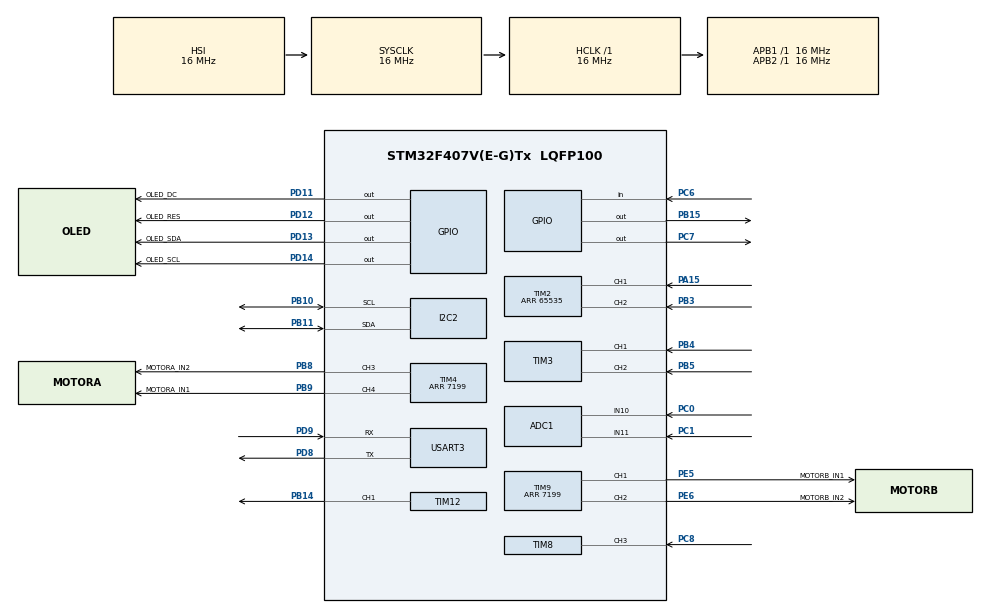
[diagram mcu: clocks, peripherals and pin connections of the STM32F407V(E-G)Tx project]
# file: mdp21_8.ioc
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ADC1.Channel-0\#ChannelRegularConversion=ADC_CHANNEL_10
ADC1.Channel-1\#ChannelRegularConversion=ADC_CHANNEL_11
ADC1.ClockPrescaler=ADC_CLOCK_SYNC_PCLK_DIV4
ADC1.NbrOfConversion=2
ADC1.NbrOfConversionFlag=1
ADC1.Rank-0\#ChannelRegularConversion=1
ADC1.Rank-1\#ChannelRegularConversion=2
ADC1.SamplingTime-0\#ChannelRegularConversion=ADC_SAMPLETIME_144CYCLES
ADC1.SamplingTime-1\#ChannelRegularConversion=ADC_SAMPLETIME_144CYCLES
ADC1.ScanConvMode=ENABLE
ADC1.master=1
FREERTOS.Tasks01=defaultTask,24,128,StartDefaultTask,Default,NULL,Dynamic,NULL,NULL
Mcu.Family=STM32F4
Mcu.Name=STM32F407V(E-G)Tx
Mcu.Package=LQFP100
NVIC.PriorityGroup=NVIC_PRIORITYGROUP_4
NVIC.TIM6_DAC_IRQn=true\:15\:0\:false\:false\:true\:false\:false\:true\:true
NVIC.TIM8_CC_IRQn=true\:5\:0\:false\:false\:true\:true\:true\:true\:true
NVIC.TimeBase=TIM6_DAC_IRQn
NVIC.TimeBaseIP=TIM6
NVIC.USART3_IRQn=true\:5\:0\:true\:false\:true\:true\:true\:true\:true
PA13.Mode=Serial_Wire
PA13.Signal=SYS_JTMS-SWDIO
PA14.Mode=Serial_Wire
PA14.Signal=SYS_JTCK-SWCLK
PA15.Signal=S_TIM2_CH1_ETR
PB10.Mode=I2C
PB10.Signal=I2C2_SCL
PB11.Mode=I2C
PB11.Signal=I2C2_SDA
PB14.Signal=S_TIM12_CH1
PB15.Signal=GPIO_Output
PB3.Signal=S_TIM2_CH2
PB4.Signal=S_TIM3_CH1
PB5.Signal=S_TIM3_CH2
PB8.GPIO_Label=MOTORA_IN2
PB8.Signal=S_TIM4_CH3
PB9.GPIO_Label=MOTORA_IN1
PB9.Signal=S_TIM4_CH4
PC0.Signal=ADCx_IN10
PC1.Signal=ADCx_IN11
PC6.Signal=GPIO_Input
PC7.Signal=GPIO_Output
PC8.Signal=S_TIM8_CH3
PD11.GPIO_Label=OLED_DC
PD11.GPIO_Speed=GPIO_SPEED_FREQ_HIGH
PD11.Signal=GPIO_Output
PD12.GPIO_Label=OLED_RES
PD12.PinState=GPIO_PIN_SET
PD12.Signal=GPIO_Output
PD13.GPIO_Label=OLED_SDA
PD13.GPIO_Speed=GPIO_SPEED_FREQ_HIGH
PD13.Signal=GPIO_Output
PD14.GPIO_Label=OLED_SCL
PD14.GPIO_Speed=GPIO_SPEED_FREQ_HIGH
PD14.Signal=GPIO_Output
PD8.Mode=Asynchronous
PD8.Signal=USART3_TX
PD9.Mode=Asynchronous
PD9.Signal=USART3_RX
PE5.GPIO_Label=MOTORB_IN1
PE5.Signal=S_TIM9_CH1
PE6.GPIO_Label=MOTORB_IN2
PE6.Signal=S_TIM9_CH2
ProjectManager.HeapSize=0x200
ProjectManager.StackSize=0x400
ProjectManager.TargetToolchain=STM32CubeIDE
RCC.AHBFreq_Value=16000000
RCC.APB1Freq_Value=16000000
RCC.APB2Freq_Value=16000000
RCC.CortexFreq_Value=16000000
RCC.HSE_VALUE=25000000
RCC.HSI_VALUE=16000000
RCC.LSE_VALUE=32768
RCC.SYSCLKFreq_VALUE=16000000
RCC.VCOOutputFreq_Value=192000000
SH.ADCx_IN10.0=ADC1_IN10,IN10
SH.ADCx_IN11.0=ADC1_IN11,IN11
SH.S_TIM12_CH1.0=TIM12_CH1,PWM Generation1 CH1
SH.S_TIM2_CH1_ETR.0=TIM2_CH1,Encoder_Interface
SH.S_TIM2_CH2.0=TIM2_CH2,Encoder_Interface
SH.S_TIM3_CH1.0=TIM3_CH1,Encoder_Interface
SH.S_TIM3_CH2.0=TIM3_CH2,Encoder_Interface
SH.S_TIM4_CH3.0=TIM4_CH3,PWM Generation3 CH3
SH.S_TIM4_CH4.0=TIM4_CH4,PWM Generation4 CH4
SH.S_TIM8_CH3.0=TIM8_CH3,Input_Capture3_from_TI3
SH.S_TIM9_CH1.0=TIM9_CH1,PWM Generation1 CH1
SH.S_TIM9_CH2.0=TIM9_CH2,PWM Generation2 CH2
TIM12.Channel-PWM\ Generation1\ CH1=TIM_CHANNEL_1
TIM12.Period=19999
TIM12.Prescaler=15
TIM12.Pulse-PWM\ Generation1\ CH1=1500
TIM2.EncoderMode=TIM_ENCODERMODE_TI12
TIM2.IC1Filter=10
TIM2.IC2Filter=10
TIM2.Period=65535
TIM3.EncoderMode=TIM_ENCODERMODE_TI12
TIM3.IC1Filter=10
TIM3.IC2Filter=10
TIM4.Channel-PWM\ Generation3\ CH3=TIM_CHANNEL_3
TIM4.Channel-PWM\ Generation4\ CH4=TIM_CHANNEL_4
TIM4.Period=7199
TIM8.Channel-Input_Capture3_from_TI3=TIM_CHANNEL_3
TIM8.ICPolarity_CH3=TIM_INPUTCHANNELPOLARITY_BOTHEDGE
TIM8.Prescaler=16-1
TIM9.Channel-PWM\ Generation1\ CH1=TIM_CHANNEL_1
TIM9.Channel-PWM\ Generation2\ CH2=TIM_CHANNEL_2
TIM9.Period=7199
USART3.VirtualMode=VM_ASYNC
VP_FREERTOS_VS_CMSIS_V2.Mode=CMSIS_V2
VP_SYS_VS_tim6.Mode=TIM6
VP_TIM4_VS_ClockSourceINT.Mode=Internal
VP_TIM8_VS_ClockSourceINT.Mode=Internal
board=custom

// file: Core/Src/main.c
/* USER CODE BEGIN Header */
/**
  ******************************************************************************
  * @file           : main.c
  * @brief          : Main program body
  ******************************************************************************
  * @attention
  *
  * Copyright (c) 2026 STMicroelectronics.
  * All rights reserved.
  *
  * This software is licensed under terms that can be found in the LICENSE file
  * in the root directory of this software component.
  * If no LICENSE file comes with this software, it is provided AS-IS.
  *
  ******************************************************************************
  */
/* USER CODE END Header */
#include "main.h"
#include "cmsis_os.h"

/* USER CODE BEGIN Includes */
#include "tests/test_runner.h"
/* USER CODE END Includes */

 ADC_HandleTypeDef hadc1;

I2C_HandleTypeDef hi2c2;

TIM_HandleTypeDef htim2;
TIM_HandleTypeDef htim3;
TIM_HandleTypeDef htim4;
TIM_HandleTypeDef htim8;
TIM_HandleTypeDef htim9;
TIM_HandleTypeDef htim12;

UART_HandleTypeDef huart3;

/* Definitions for defaultTask */
osThreadId_t defaultTaskHandle;
const osThreadAttr_t defaultTask_attributes = {
  .name = "defaultTask",
  .stack_size = 128 * 4,
  .priority = (osPriority_t) osPriorityNormal,
};

void SystemClock_Config(void);
static void MX_GPIO_Init(void);
static void MX_I2C2_Init(void);
static void MX_TIM2_Init(void);
static void MX_TIM3_Init(void);
static void MX_TIM4_Init(void);
static void MX_TIM9_Init(void);
static void MX_TIM12_Init(void);
static void MX_USART3_UART_Init(void);
static void MX_ADC1_Init(void);
static void MX_TIM8_Init(void);
void StartDefaultTask(void *argument);

int main(void)
{

  /* MCU Configuration--------------------------------------------------------*/

  /* Reset of all peripherals, Initializes the Flash interface and the Systick. */
  HAL_Init();

  /* Configure the system clock */
  SystemClock_Config();

  /* Initialize all configured peripherals */
  MX_GPIO_Init();
  MX_I2C2_Init();
  MX_TIM2_Init();
  MX_TIM3_Init();
  MX_TIM4_Init();
  MX_TIM9_Init();
  MX_TIM12_Init();
  MX_USART3_UART_Init();
  MX_ADC1_Init();
  MX_TIM8_Init();
  /* USER CODE BEGIN 2 */

  Test_RunSelected();

  /* USER CODE END 2 */

  /* Init scheduler */
  osKernelInitialize();

  /* Create the thread(s) */
  /* creation of defaultTask */
  defaultTaskHandle = osThreadNew(StartDefaultTask, NULL, &defaultTask_attributes);

  /* Start scheduler */
  osKernelStart();

  /* We should never get here as control is now taken by the scheduler */
  /* Infinite loop */
  while (1)
  {

  }
}

void SystemClock_Config(void)
{
  RCC_OscInitTypeDef RCC_OscInitStruct = {0};
  RCC_ClkInitTypeDef RCC_ClkInitStruct = {0};

  /** Configure the main internal regulator output voltage
  */
  __HAL_RCC_PWR_CLK_ENABLE();
  __HAL_PWR_VOLTAGESCALING_CONFIG(PWR_REGULATOR_VOLTAGE_SCALE1);

  /** Initializes the RCC Oscillators according to the specified parameters
  * in the RCC_OscInitTypeDef structure.
  */
  RCC_OscInitStruct.OscillatorType = RCC_OSCILLATORTYPE_HSI;
  RCC_OscInitStruct.HSIState = RCC_HSI_ON;
  RCC_OscInitStruct.HSICalibrationValue = RCC_HSICALIBRATION_DEFAULT;
  RCC_OscInitStruct.PLL.PLLState = RCC_PLL_NONE;
  if (HAL_RCC_OscConfig(&RCC_OscInitStruct) != HAL_OK)
  {
    Error_Handler();
  }

  /** Initializes the CPU, AHB and APB buses clocks
  */
  RCC_ClkInitStruct.ClockType = RCC_CLOCKTYPE_HCLK|RCC_CLOCKTYPE_SYSCLK
                              |RCC_CLOCKTYPE_PCLK1|RCC_CLOCKTYPE_PCLK2;
  RCC_ClkInitStruct.SYSCLKSource = RCC_SYSCLKSOURCE_HSI;
  RCC_ClkInitStruct.AHBCLKDivider = RCC_SYSCLK_DIV1;
  RCC_ClkInitStruct.APB1CLKDivider = RCC_HCLK_DIV1;
  RCC_ClkInitStruct.APB2CLKDivider = RCC_HCLK_DIV1;

  if (HAL_RCC_ClockConfig(&RCC_ClkInitStruct, FLASH_LATENCY_0) != HAL_OK)
  {
    Error_Handler();
  }
}

static void MX_ADC1_Init(void)
{

  ADC_ChannelConfTypeDef sConfig = {0};

  /** Configure the global features of the ADC (Clock, Resolution, Data Alignment and number of conversion)
  */
  hadc1.Instance = ADC1;
  hadc1.Init.ClockPrescaler = ADC_CLOCK_SYNC_PCLK_DIV4;
  hadc1.Init.Resolution = ADC_RESOLUTION_12B;
  hadc1.Init.ScanConvMode = ENABLE;
  hadc1.Init.ContinuousConvMode = DISABLE;
  hadc1.Init.DiscontinuousConvMode = DISABLE;
  hadc1.Init.ExternalTrigConvEdge = ADC_EXTERNALTRIGCONVEDGE_NONE;
  hadc1.Init.ExternalTrigConv = ADC_SOFTWARE_START;
  hadc1.Init.DataAlign = ADC_DATAALIGN_RIGHT;
  hadc1.Init.NbrOfConversion = 2;
  hadc1.Init.DMAContinuousRequests = DISABLE;
  hadc1.Init.EOCSelection = ADC_EOC_SINGLE_CONV;
  if (HAL_ADC_Init(&hadc1) != HAL_OK)
  {
    Error_Handler();
  }

  /** Configure for the selected ADC regular channel its corresponding rank in the sequencer and its sample time.
  */
  sConfig.Channel = ADC_CHANNEL_10;
  sConfig.Rank = 1;
  sConfig.SamplingTime = ADC_SAMPLETIME_144CYCLES;
  if (HAL_ADC_ConfigChannel(&hadc1, &sConfig) != HAL_OK)
  {
    Error_Handler();
  }

  /** Configure for the selected ADC regular channel its corresponding rank in the sequencer and its sample time.
  */
  sConfig.Channel = ADC_CHANNEL_11;
  sConfig.Rank = 2;
  if (HAL_ADC_ConfigChannel(&hadc1, &sConfig) != HAL_OK)
  {
    Error_Handler();
  }

}

static void MX_I2C2_Init(void)
{

  hi2c2.Instance = I2C2;
  hi2c2.Init.ClockSpeed = 100000;
  hi2c2.Init.DutyCycle = I2C_DUTYCYCLE_2;
  hi2c2.Init.OwnAddress1 = 0;
  hi2c2.Init.AddressingMode = I2C_ADDRESSINGMODE_7BIT;
  hi2c2.Init.DualAddressMode = I2C_DUALADDRESS_DISABLE;
  hi2c2.Init.OwnAddress2 = 0;
  hi2c2.Init.GeneralCallMode = I2C_GENERALCALL_DISABLE;
  hi2c2.Init.NoStretchMode = I2C_NOSTRETCH_DISABLE;
  if (HAL_I2C_Init(&hi2c2) != HAL_OK)
  {
    Error_Handler();
  }

}

static void MX_TIM2_Init(void)
{

  TIM_Encoder_InitTypeDef sConfig = {0};
  TIM_MasterConfigTypeDef sMasterConfig = {0};

  htim2.Instance = TIM2;
  htim2.Init.Prescaler = 0;
  htim2.Init.CounterMode = TIM_COUNTERMODE_UP;
  htim2.Init.Period = 65535;
  htim2.Init.ClockDivision = TIM_CLOCKDIVISION_DIV1;
  htim2.Init.AutoReloadPreload = TIM_AUTORELOAD_PRELOAD_DISABLE;
  sConfig.EncoderMode = TIM_ENCODERMODE_TI12;
  sConfig.IC1Polarity = TIM_ICPOLARITY_RISING;
  sConfig.IC1Selection = TIM_ICSELECTION_DIRECTTI;
  sConfig.IC1Prescaler = TIM_ICPSC_DIV1;
  sConfig.IC1Filter = 10;
  sConfig.IC2Polarity = TIM_ICPOLARITY_RISING;
  sConfig.IC2Selection = TIM_ICSELECTION_DIRECTTI;
  sConfig.IC2Prescaler = TIM_ICPSC_DIV1;
  sConfig.IC2Filter = 10;
  if (HAL_TIM_Encoder_Init(&htim2, &sConfig) != HAL_OK)
  {
    Error_Handler();
  }
  sMasterConfig.MasterOutputTrigger = TIM_TRGO_RESET;
  sMasterConfig.MasterSlaveMode = TIM_MASTERSLAVEMODE_DISABLE;
  if (HAL_TIMEx_MasterConfigSynchronization(&htim2, &sMasterConfig) != HAL_OK)
  {
    Error_Handler();
  }

}

static void MX_TIM3_Init(void)
{

  TIM_Encoder_InitTypeDef sConfig = {0};
  TIM_MasterConfigTypeDef sMasterConfig = {0};

  htim3.Instance = TIM3;
  htim3.Init.Prescaler = 0;
  htim3.Init.CounterMode = TIM_COUNTERMODE_UP;
  htim3.Init.Period = 65535;
  htim3.Init.ClockDivision = TIM_CLOCKDIVISION_DIV1;
  htim3.Init.AutoReloadPreload = TIM_AUTORELOAD_PRELOAD_DISABLE;
  sConfig.EncoderMode = TIM_ENCODERMODE_TI12;
  sConfig.IC1Polarity = TIM_ICPOLARITY_RISING;
  sConfig.IC1Selection = TIM_ICSELECTION_DIRECTTI;
  sConfig.IC1Prescaler = TIM_ICPSC_DIV1;
  sConfig.IC1Filter = 10;
  sConfig.IC2Polarity = TIM_ICPOLARITY_RISING;
  sConfig.IC2Selection = TIM_ICSELECTION_DIRECTTI;
  sConfig.IC2Prescaler = TIM_ICPSC_DIV1;
  sConfig.IC2Filter = 10;
  if (HAL_TIM_Encoder_Init(&htim3, &sConfig) != HAL_OK)
  {
    Error_Handler();
  }
  sMasterConfig.MasterOutputTrigger = TIM_TRGO_RESET;
  sMasterConfig.MasterSlaveMode = TIM_MASTERSLAVEMODE_DISABLE;
  if (HAL_TIMEx_MasterConfigSynchronization(&htim3, &sMasterConfig) != HAL_OK)
  {
    Error_Handler();
  }

}

static void MX_TIM4_Init(void)
{

  TIM_ClockConfigTypeDef sClockSourceConfig = {0};
  TIM_MasterConfigTypeDef sMasterConfig = {0};
  TIM_OC_InitTypeDef sConfigOC = {0};

  htim4.Instance = TIM4;
  htim4.Init.Prescaler = 0;
  htim4.Init.CounterMode = TIM_COUNTERMODE_UP;
  htim4.Init.Period = 7199;
  htim4.Init.ClockDivision = TIM_CLOCKDIVISION_DIV1;
  htim4.Init.AutoReloadPreload = TIM_AUTORELOAD_PRELOAD_DISABLE;
  if (HAL_TIM_Base_Init(&htim4) != HAL_OK)
  {
    Error_Handler();
  }
  sClockSourceConfig.ClockSource = TIM_CLOCKSOURCE_INTERNAL;
  if (HAL_TIM_ConfigClockSource(&htim4, &sClockSourceConfig) != HAL_OK)
  {
    Error_Handler();
  }
  if (HAL_TIM_PWM_Init(&htim4) != HAL_OK)
  {
    Error_Handler();
  }
  sMasterConfig.MasterOutputTrigger = TIM_TRGO_RESET;
  sMasterConfig.MasterSlaveMode = TIM_MASTERSLAVEMODE_DISABLE;
  if (HAL_TIMEx_MasterConfigSynchronization(&htim4, &sMasterConfig) != HAL_OK)
  {
    Error_Handler();
  }
  sConfigOC.OCMode = TIM_OCMODE_PWM1;
  sConfigOC.Pulse = 0;
  sConfigOC.OCPolarity = TIM_OCPOLARITY_HIGH;
  sConfigOC.OCFastMode = TIM_OCFAST_DISABLE;
  if (HAL_TIM_PWM_ConfigChannel(&htim4, &sConfigOC, TIM_CHANNEL_3) != HAL_OK)
  {
    Error_Handler();
  }
  if (HAL_TIM_PWM_ConfigChannel(&htim4, &sConfigOC, TIM_CHANNEL_4) != HAL_OK)
  {
    Error_Handler();
  }
  HAL_TIM_MspPostInit(&htim4);

}

static void MX_TIM8_Init(void)
{

  TIM_ClockConfigTypeDef sClockSourceConfig = {0};
  TIM_MasterConfigTypeDef sMasterConfig = {0};
  TIM_IC_InitTypeDef sConfigIC = {0};

  htim8.Instance = TIM8;
  htim8.Init.Prescaler = 16-1;
  htim8.Init.CounterMode = TIM_COUNTERMODE_UP;
  htim8.Init.Period = 65535;
  htim8.Init.ClockDivision = TIM_CLOCKDIVISION_DIV1;
  htim8.Init.RepetitionCounter = 0;
  htim8.Init.AutoReloadPreload = TIM_AUTORELOAD_PRELOAD_DISABLE;
  if (HAL_TIM_Base_Init(&htim8) != HAL_OK)
  {
    Error_Handler();
  }
  sClockSourceConfig.ClockSource = TIM_CLOCKSOURCE_INTERNAL;
  if (HAL_TIM_ConfigClockSource(&htim8, &sClockSourceConfig) != HAL_OK)
  {
    Error_Handler();
  }
  if (HAL_TIM_IC_Init(&htim8) != HAL_OK)
  {
    Error_Handler();
  }
  sMasterConfig.MasterOutputTrigger = TIM_TRGO_RESET;
  sMasterConfig.MasterSlaveMode = TIM_MASTERSLAVEMODE_DISABLE;
  if (HAL_TIMEx_MasterConfigSynchronization(&htim8, &sMasterConfig) != HAL_OK)
  {
    Error_Handler();
  }
  sConfigIC.ICPolarity = TIM_INPUTCHANNELPOLARITY_BOTHEDGE;
  sConfigIC.ICSelection = TIM_ICSELECTION_DIRECTTI;
  sConfigIC.ICPrescaler = TIM_ICPSC_DIV1;
  sConfigIC.ICFilter = 0;
  if (HAL_TIM_IC_ConfigChannel(&htim8, &sConfigIC, TIM_CHANNEL_3) != HAL_OK)
  {
    Error_Handler();
  }

}

static void MX_TIM9_Init(void)
{

  TIM_OC_InitTypeDef sConfigOC = {0};

  htim9.Instance = TIM9;
  htim9.Init.Prescaler = 0;
  htim9.Init.CounterMode = TIM_COUNTERMODE_UP;
  htim9.Init.Period = 7199;
  htim9.Init.ClockDivision = TIM_CLOCKDIVISION_DIV1;
  htim9.Init.AutoReloadPreload = TIM_AUTORELOAD_PRELOAD_DISABLE;
  if (HAL_TIM_PWM_Init(&htim9) != HAL_OK)
  {
    Error_Handler();
  }
  sConfigOC.OCMode = TIM_OCMODE_PWM1;
  sConfigOC.Pulse = 0;
  sConfigOC.OCPolarity = TIM_OCPOLARITY_HIGH;
  sConfigOC.OCFastMode = TIM_OCFAST_DISABLE;
  if (HAL_TIM_PWM_ConfigChannel(&htim9, &sConfigOC, TIM_CHANNEL_1) != HAL_OK)
  {
    Error_Handler();
  }
  if (HAL_TIM_PWM_ConfigChannel(&htim9, &sConfigOC, TIM_CHANNEL_2) != HAL_OK)
  {
    Error_Handler();
  }
  HAL_TIM_MspPostInit(&htim9);

}

static void MX_TIM12_Init(void)
{

  TIM_OC_InitTypeDef sConfigOC = {0};

  htim12.Instance = TIM12;
  htim12.Init.Prescaler = 15;
  htim12.Init.CounterMode = TIM_COUNTERMODE_UP;
  htim12.Init.Period = 19999;
  htim12.Init.ClockDivision = TIM_CLOCKDIVISION_DIV1;
  htim12.Init.AutoReloadPreload = TIM_AUTORELOAD_PRELOAD_DISABLE;
  if (HAL_TIM_PWM_Init(&htim12) != HAL_OK)
  {
    Error_Handler();
  }
  sConfigOC.OCMode = TIM_OCMODE_PWM1;
  sConfigOC.Pulse = 1500;
  sConfigOC.OCPolarity = TIM_OCPOLARITY_HIGH;
  sConfigOC.OCFastMode = TIM_OCFAST_DISABLE;
  if (HAL_TIM_PWM_ConfigChannel(&htim12, &sConfigOC, TIM_CHANNEL_1) != HAL_OK)
  {
    Error_Handler();
  }
  HAL_TIM_MspPostInit(&htim12);

}

static void MX_USART3_UART_Init(void)
{

  huart3.Instance = USART3;
  huart3.Init.BaudRate = 115200;
  huart3.Init.WordLength = UART_WORDLENGTH_8B;
  huart3.Init.StopBits = UART_STOPBITS_1;
  huart3.Init.Parity = UART_PARITY_NONE;
  huart3.Init.Mode = UART_MODE_TX_RX;
  huart3.Init.HwFlowCtl = UART_HWCONTROL_NONE;
  huart3.Init.OverSampling = UART_OVERSAMPLING_16;
  if (HAL_UART_Init(&huart3) != HAL_OK)
  {
    Error_Handler();
  }

}

static void MX_GPIO_Init(void)
{
  GPIO_InitTypeDef GPIO_InitStruct = {0};

  /* GPIO Ports Clock Enable */
  __HAL_RCC_GPIOE_CLK_ENABLE();
  __HAL_RCC_GPIOC_CLK_ENABLE();
  __HAL_RCC_GPIOB_CLK_ENABLE();
  __HAL_RCC_GPIOD_CLK_ENABLE();
  __HAL_RCC_GPIOA_CLK_ENABLE();

  /*Configure GPIO pin Output Level */
  HAL_GPIO_WritePin(GPIOB, GPIO_PIN_15, GPIO_PIN_RESET);

  /*Configure GPIO pin Output Level */
  HAL_GPIO_WritePin(GPIOD, OLED_DC_Pin|OLED_SDA_Pin|OLED_SCL_Pin, GPIO_PIN_RESET);

  /*Configure GPIO pin Output Level */
  HAL_GPIO_WritePin(OLED_RES_GPIO_Port, OLED_RES_Pin, GPIO_PIN_SET);

  /*Configure GPIO pin Output Level */
  HAL_GPIO_WritePin(GPIOC, GPIO_PIN_7, GPIO_PIN_RESET);

  /*Configure GPIO pin : PB15 */
  GPIO_InitStruct.Pin = GPIO_PIN_15;
  GPIO_InitStruct.Mode = GPIO_MODE_OUTPUT_PP;
  GPIO_InitStruct.Pull = GPIO_NOPULL;
  GPIO_InitStruct.Speed = GPIO_SPEED_FREQ_LOW;
  HAL_GPIO_Init(GPIOB, &GPIO_InitStruct);

  /*Configure GPIO pins : OLED_DC_Pin OLED_SDA_Pin OLED_SCL_Pin */
  GPIO_InitStruct.Pin = OLED_DC_Pin|OLED_SDA_Pin|OLED_SCL_Pin;
  GPIO_InitStruct.Mode = GPIO_MODE_OUTPUT_PP;
  GPIO_InitStruct.Pull = GPIO_NOPULL;
  GPIO_InitStruct.Speed = GPIO_SPEED_FREQ_HIGH;
  HAL_GPIO_Init(GPIOD, &GPIO_InitStruct);

  /*Configure GPIO pin : OLED_RES_Pin */
  GPIO_InitStruct.Pin = OLED_RES_Pin;
  GPIO_InitStruct.Mode = GPIO_MODE_OUTPUT_PP;
  GPIO_InitStruct.Pull = GPIO_NOPULL;
  GPIO_InitStruct.Speed = GPIO_SPEED_FREQ_LOW;
  HAL_GPIO_Init(OLED_RES_GPIO_Port, &GPIO_InitStruct);

  /*Configure GPIO pin : PC6 */
  GPIO_InitStruct.Pin = GPIO_PIN_6;
  GPIO_InitStruct.Mode = GPIO_MODE_INPUT;
  GPIO_InitStruct.Pull = GPIO_NOPULL;
  HAL_GPIO_Init(GPIOC, &GPIO_InitStruct);

  /*Configure GPIO pin : PC7 */
  GPIO_InitStruct.Pin = GPIO_PIN_7;
  GPIO_InitStruct.Mode = GPIO_MODE_OUTPUT_PP;
  GPIO_InitStruct.Pull = GPIO_NOPULL;
  GPIO_InitStruct.Speed = GPIO_SPEED_FREQ_LOW;
  HAL_GPIO_Init(GPIOC, &GPIO_InitStruct);

}

void StartDefaultTask(void *argument)
{
  for(;;)
  {
    osDelay(1);
  }
}

void HAL_TIM_PeriodElapsedCallback(TIM_HandleTypeDef *htim)
{
  if (htim->Instance == TIM6) {
    HAL_IncTick();
  }
}

void Error_Handler(void)
{
  __disable_irq();
  while (1)
  {
  }
}
